AUTOSAR XML (schema 4-2-2)
package /Components
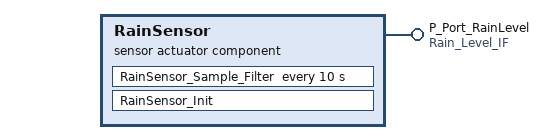
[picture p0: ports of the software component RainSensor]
  sensor actuator sw component type RainSensor
    provide port P_Port_RainLevel: provided-interface=Rain_Level_IF
    behavior RainSensor_InternalBehavior
      init event RainSensor_InitEvent: start-on-event=RainSensor_Init
      timing event RainSensor_CycleEvent: start-on-event=RainSensor_Sample_Filter, period=10
      runnable RainSensor_Init
        data-send-points:
          access VA_RainIntensity_Init: accessed-variable=P_Port_RainLevel.rain_intensity
      runnable RainSensor_Sample_Filter: minimum-start-interval=10
        data-send-points:
          access VA_RainIntensity_Cycle: accessed-variable=P_Port_RainLevel.rain_intensity
